// Description:

// Created:

// Author:

// Version:

// Vehicle Project:

LIN_description_file;
LIN_protocol_version = "2.1";
LIN_language_version = "2.1";
LIN_speed = 19.2 kbps;

Nodes {
  Master: VCU, 5 ms, 0.1 ms ;
  Slaves: ERV, EXV_1, EXV_2, PMP_1, PMP_2, SVA, HVCH ;
}

Signals {
  HVCH_IntelTemp: 8, 0, HVCH, VCU ;
  Calibration_sta: 2, 0, SVA, VCU ;
  Blockage_Fault_STA: 1, 0, SVA, VCU ;
  Breakage_Fault_STA: 1, 0, SVA, VCU ;
  Act_Pos_sta: 12, 0, SVA, VCU ;
  LIN_Resp_Error_sta: 1, 0, SVA, VCU ;
  EXV1_ResponseError: 1, 0, EXV_1, VCU ;
  EXV1_CurrentInitState: 2, 0, EXV_1, VCU ;
  EXV1_RunState: 1, 0, EXV_1, VCU ;
  EXV1_FaultState: 4, 0, EXV_1, VCU ;
  EXV1_VoltageState: 2, 0, EXV_1, VCU ;
  EXV1_TemperatureWarn: 2, 0, EXV_1, VCU ;
  EXV1_CurrentPosition: 16, 0, EXV_1, VCU ;
  HVCH_HV_DC_curr: 8, 0, HVCH, VCU ;
  HVCH_HV_voltage: 8, 0, HVCH, VCU ;
  HVCH_MediumTemp: 8, 0, HVCH, VCU ;
  HVCH_DutyCycle: 8, 50, HVCH, VCU ;
  HVCH_Status: 3, 0, HVCH, VCU ;
  HVCH_defectHeaterCircuits: 3, 0, HVCH, VCU ;
  HVCH_HV_Voltage_Valid: 2, 0, HVCH, VCU ;
  HVCH_TempSens_Flt: 1, 0, HVCH, VCU ;
  HVCH_TempLim: 1, 0, HVCH, VCU ;
  HVCH_LIN_Flt: 1, 0, HVCH, VCU ;
  HVCH_ExtPwrSup_Flt: 1, 0, HVCH, VCU ;
  HVCH_Off_ShrtCurr: 1, 0, HVCH, VCU ;
  HVCH_InternalPCBTemp: 8, 0, HVCH, VCU ;
  HVCH_CurrSens_Flt: 5, 0, HVCH, VCU ;
  HVCH_RsErr: 1, 0, HVCH, VCU ;
  RsErr_EXV2: 1, 0, ERV, VCU ;
  EXV2_curInit_Stat: 2, 0, ERV, VCU ;
  EXV2_Run_Stat: 1, 0, ERV, VCU ;
  EXV2_Fault_Stat: 4, 0, ERV, VCU ;
  EXV2_Volt_Stat: 2, 0, ERV, VCU ;
  EXV2_OvrTemp_Warn: 2, 0, ERV, VCU ;
  EXV2_Pos: 16, 0, ERV, VCU ;
  PMP3_RESP_ERROR: 1, 0, PMP_2, VCU ;
  PMP3_PumpMotorSta: 2, 0, PMP_2, VCU ;
  PMP3_PumpDryRunningSta: 1, 0, PMP_2, VCU ;
  PMP3_PumpPowerSta: 2, 0, PMP_2, VCU ;
  PMP3_PumpTempSta: 2, 0, PMP_2, VCU ;
  PMP3_PumpInputVolt: 8, 0, PMP_2, VCU ;
  PMP3_RealRPM: 8, 0, PMP_2, VCU ;
  Calibration_cmd: 1, 0, VCU, SVA ;
  Target_Pos_cmd: 12, 0, VCU, SVA ;
  EXV2_ResponseError: 1, 0, EXV_2, VCU ;
  EXV2_CurrentInitState: 2, 0, EXV_2, VCU ;
  EXV2_RunState: 1, 0, EXV_2, VCU ;
  EXV2_FaultState: 4, 0, EXV_2, VCU ;
  EXV2_VoltageState: 2, 0, EXV_2, VCU ;
  EXV2_TemperatureWarn: 2, 0, EXV_2, VCU ;
  EXV2_CurrentPosition: 16, 0, EXV_2, VCU ;
  ECC_PMP2_SpdSet: 8, 0, VCU, PMP_1 ;
  ECC_PMP3_SpdSet: 8, 0, VCU, PMP_2 ;
  EDCU_EXV2_Cmd_Set_Rq: 16, 0, VCU, ERV ;
  EDCU_EXV2_Cmd_Move_Enbl: 1, 0, VCU, ERV ;
  EDCU_EXV2_Cmd_Init_Rq: 3, 0, VCU, ERV ;
  TMM_EXV2_PositionRequest: 16, 0, VCU, EXV_2 ;
  TMM_EXV2_EnableRequest: 1, 0, VCU, EXV_2 ;
  TMM_EXV2_initRequest: 3, 0, VCU, EXV_2 ;
  TMM_EXV1_PositionRequest: 16, 0, VCU, EXV_1 ;
  TMM_EXV1_EnableRequest: 1, 0, VCU, EXV_1 ;
  TMM_EXV1_initRequest: 3, 0, VCU, EXV_1 ;
  PMP2_RESP_ERROR: 1, 0, PMP_1, VCU ;
  PMP2_PumpMotorSta: 2, 0, PMP_1, VCU ;
  PMP2_PumpDryRunningSta: 1, 0, PMP_1, VCU ;
  PMP2_PumpPowerSta: 2, 0, PMP_1, VCU ;
  PMP2_PumpTempSta: 2, 0, PMP_1, VCU ;
  PMP2_PumpInputVolt: 8, 0, PMP_1, VCU ;
  PMP2_RealRPM: 8, 0, PMP_1, VCU ;
  TCU_HVCH_heating_rq: 7, 0, VCU, HVCH ;
  TCU_HVCH_On_Rq: 2, 0, VCU, HVCH ;
  TCU_HVCHMaxPowerLimit: 8, 0, VCU, HVCH ;
  TCU_HVCH_TmaxLim_output: 8, 0, VCU, HVCH ;
}

Frames {
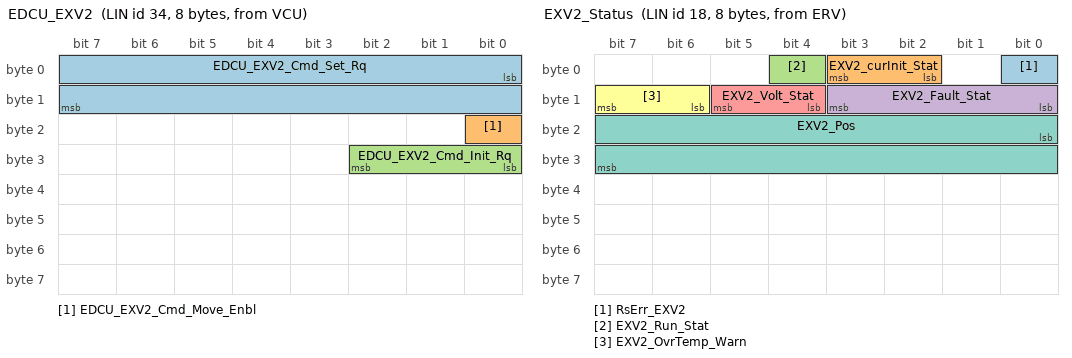
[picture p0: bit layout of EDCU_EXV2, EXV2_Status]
  EDCU_EXV2: 34, VCU, 8 {
    EDCU_EXV2_Cmd_Set_Rq, 0 ;
    EDCU_EXV2_Cmd_Move_Enbl, 16 ;
    EDCU_EXV2_Cmd_Init_Rq, 24 ;
  }
  EXV2_Status: 18, ERV, 8 {
    RsErr_EXV2, 0 ;
    EXV2_curInit_Stat, 2 ;
    EXV2_Run_Stat, 4 ;
    EXV2_Fault_Stat, 8 ;
    EXV2_Volt_Stat, 12 ;
    EXV2_OvrTemp_Warn, 14 ;
    EXV2_Pos, 16 ;
  }
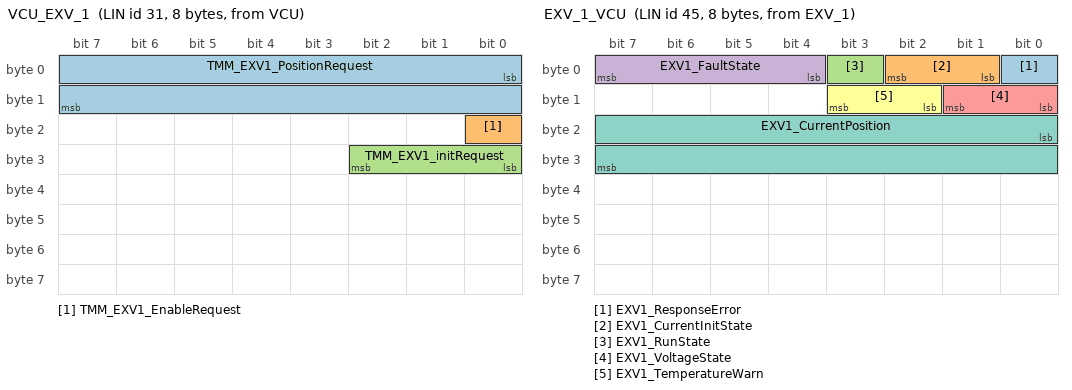
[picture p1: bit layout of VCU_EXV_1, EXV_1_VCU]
  VCU_EXV_1: 31, VCU, 8 {
    TMM_EXV1_PositionRequest, 0 ;
    TMM_EXV1_EnableRequest, 16 ;
    TMM_EXV1_initRequest, 24 ;
  }
  EXV_1_VCU: 45, EXV_1, 8 {
    EXV1_ResponseError, 0 ;
    EXV1_CurrentInitState, 1 ;
    EXV1_RunState, 3 ;
    EXV1_FaultState, 4 ;
    EXV1_VoltageState, 8 ;
    EXV1_TemperatureWarn, 10 ;
    EXV1_CurrentPosition, 16 ;
  }
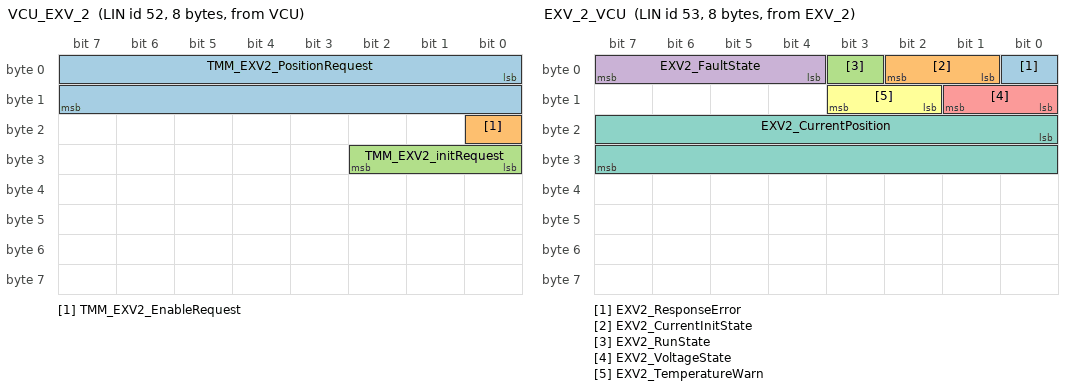
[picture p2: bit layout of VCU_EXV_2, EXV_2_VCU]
  VCU_EXV_2: 52, VCU, 8 {
    TMM_EXV2_PositionRequest, 0 ;
    TMM_EXV2_EnableRequest, 16 ;
    TMM_EXV2_initRequest, 24 ;
  }
  EXV_2_VCU: 53, EXV_2, 8 {
    EXV2_ResponseError, 0 ;
    EXV2_CurrentInitState, 1 ;
    EXV2_RunState, 3 ;
    EXV2_FaultState, 4 ;
    EXV2_VoltageState, 8 ;
    EXV2_TemperatureWarn, 10 ;
    EXV2_CurrentPosition, 16 ;
  }
  PMP_Cmd: 36, VCU, 8 {
    ECC_PMP2_SpdSet, 8 ;
    ECC_PMP3_SpdSet, 16 ;
  }
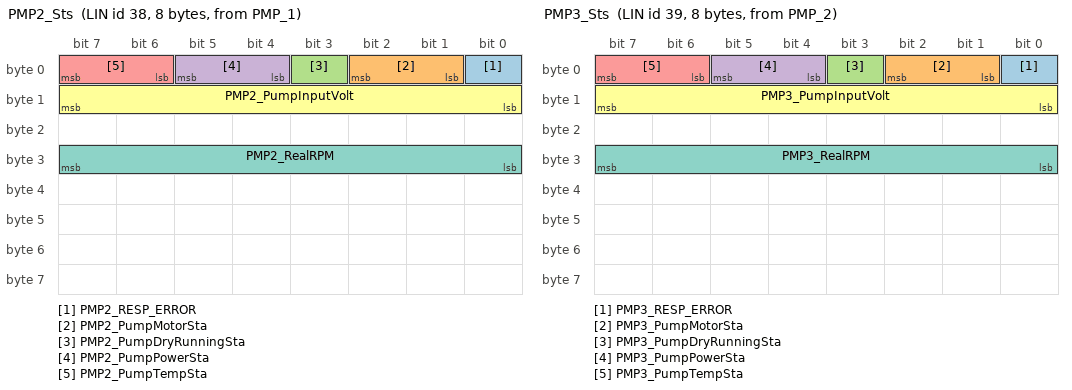
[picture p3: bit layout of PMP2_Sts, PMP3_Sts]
  PMP2_Sts: 38, PMP_1, 8 {
    PMP2_RESP_ERROR, 0 ;
    PMP2_PumpMotorSta, 1 ;
    PMP2_PumpDryRunningSta, 3 ;
    PMP2_PumpPowerSta, 4 ;
    PMP2_PumpTempSta, 6 ;
    PMP2_PumpInputVolt, 8 ;
    PMP2_RealRPM, 24 ;
  }
  PMP3_Sts: 39, PMP_2, 8 {
    PMP3_RESP_ERROR, 0 ;
    PMP3_PumpMotorSta, 1 ;
    PMP3_PumpDryRunningSta, 3 ;
    PMP3_PumpPowerSta, 4 ;
    PMP3_PumpTempSta, 6 ;
    PMP3_PumpInputVolt, 8 ;
    PMP3_RealRPM, 24 ;
  }
  VCU_SVA_CMD: 16, VCU, 8 {
    Calibration_cmd, 8 ;
    Target_Pos_cmd, 16 ;
  }
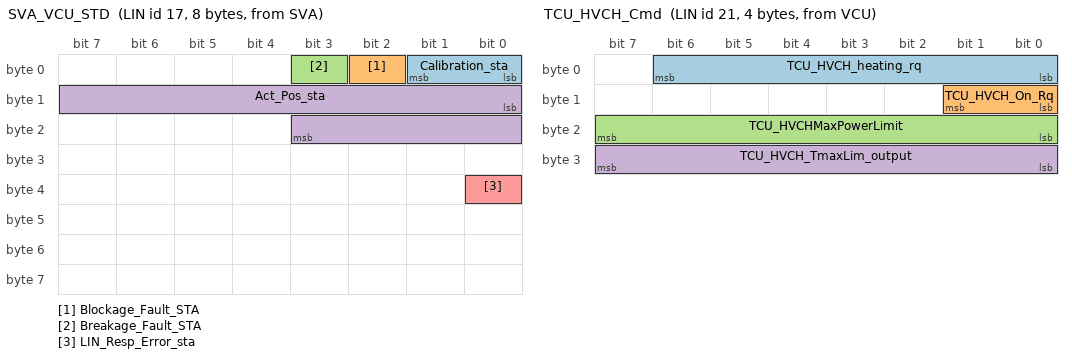
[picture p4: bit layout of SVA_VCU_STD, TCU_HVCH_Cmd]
  SVA_VCU_STD: 17, SVA, 8 {
    Calibration_sta, 0 ;
    Blockage_Fault_STA, 2 ;
    Breakage_Fault_STA, 3 ;
    Act_Pos_sta, 8 ;
    LIN_Resp_Error_sta, 32 ;
  }
  TCU_HVCH_Cmd: 21, VCU, 4 {
    TCU_HVCH_heating_rq, 0 ;
    TCU_HVCH_On_Rq, 8 ;
    TCU_HVCHMaxPowerLimit, 16 ;
    TCU_HVCH_TmaxLim_output, 24 ;
  }
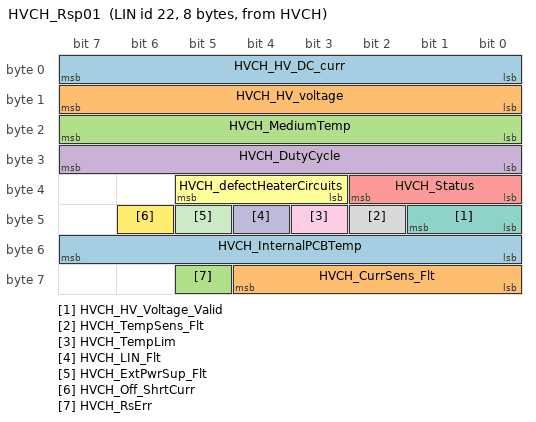
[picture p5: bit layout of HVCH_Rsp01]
  HVCH_Rsp01: 22, HVCH, 8 {
    HVCH_HV_DC_curr, 0 ;
    HVCH_HV_voltage, 8 ;
    HVCH_MediumTemp, 16 ;
    HVCH_DutyCycle, 24 ;
    HVCH_Status, 32 ;
    HVCH_defectHeaterCircuits, 35 ;
    HVCH_HV_Voltage_Valid, 40 ;
    HVCH_TempSens_Flt, 42 ;
    HVCH_TempLim, 43 ;
    HVCH_LIN_Flt, 44 ;
    HVCH_ExtPwrSup_Flt, 45 ;
    HVCH_Off_ShrtCurr, 46 ;
    HVCH_InternalPCBTemp, 48 ;
    HVCH_CurrSens_Flt, 56 ;
    HVCH_RsErr, 61 ;
  }
  HVCH_Rsp02: 23, HVCH, 8 {
    HVCH_IntelTemp, 0 ;
  }
}

Node_attributes {
  ERV{
    LIN_protocol = "2.1" ;
    configured_NAD = 0x62 ;
    initial_NAD = 0x62 ;
    product_id = 0x0, 0x0, 0 ;
    P2_min = 50 ms ;
    ST_min = 0 ms ;
    N_As_timeout = 1000 ms ;
    N_Cr_timeout = 1000 ms ;
    configurable_frames {
      EDCU_EXV2 ;
      EXV2_Status ;
    }
  }
  EXV_1{
    LIN_protocol = "2.1" ;
    configured_NAD = 0x63 ;
    initial_NAD = 0x63 ;
    product_id = 0x0, 0x0, 0 ;
    P2_min = 50 ms ;
    ST_min = 0 ms ;
    N_As_timeout = 1000 ms ;
    N_Cr_timeout = 1000 ms ;
    configurable_frames {
      VCU_EXV_1 ;
      EXV_1_VCU ;
    }
  }
  EXV_2{
    LIN_protocol = "2.1" ;
    configured_NAD = 0x64 ;
    initial_NAD = 0x64 ;
    product_id = 0x0, 0x0, 0 ;
    P2_min = 50 ms ;
    ST_min = 0 ms ;
    N_As_timeout = 1000 ms ;
    N_Cr_timeout = 1000 ms ;
    configurable_frames {
      VCU_EXV_2 ;
      EXV_2_VCU ;
    }
  }
  PMP_1{
    LIN_protocol = "2.1" ;
    configured_NAD = 0x74 ;
    initial_NAD = 0x74 ;
    product_id = 0x0, 0x0, 0 ;
    P2_min = 50 ms ;
    ST_min = 0 ms ;
    N_As_timeout = 1000 ms ;
    N_Cr_timeout = 1000 ms ;
    configurable_frames {
      PMP_Cmd ;
      PMP2_Sts ;
    }
  }
  PMP_2{
    LIN_protocol = "2.1" ;
    configured_NAD = 0x75 ;
    initial_NAD = 0x75 ;
    product_id = 0x0, 0x0, 0 ;
    P2_min = 50 ms ;
    ST_min = 0 ms ;
    N_As_timeout = 1000 ms ;
    N_Cr_timeout = 1000 ms ;
    configurable_frames {
      PMP_Cmd ;
      PMP3_Sts ;
    }
  }
  SVA{
    LIN_protocol = "2.1" ;
    configured_NAD = 0x65 ;
    initial_NAD = 0x65 ;
    product_id = 0x0, 0x0, 0 ;
    P2_min = 50 ms ;
    ST_min = 0 ms ;
    N_As_timeout = 1000 ms ;
    N_Cr_timeout = 1000 ms ;
    configurable_frames {
      VCU_SVA_CMD ;
      SVA_VCU_STD ;
    }
  }
  HVCH{
    LIN_protocol = "2.1" ;
    configured_NAD = 0x5B ;
    initial_NAD = 0x5B ;
    product_id = 0x0, 0x0, 0 ;
    P2_min = 50 ms ;
    ST_min = 0 ms ;
    N_As_timeout = 1000 ms ;
    N_Cr_timeout = 1000 ms ;
    configurable_frames {
      TCU_HVCH_Cmd ;
      HVCH_Rsp01 ;
      HVCH_Rsp02 ;
    }
  }
}

Schedule_tables {
 TCU_LIN_Schedule {
    EDCU_EXV2 delay 10 ms ;
    EXV2_Status delay 10 ms ;
    VCU_EXV_1 delay 100 ms ;
    EXV_1_VCU delay 100 ms ;
    VCU_EXV_2 delay 100 ms ;
    EXV_2_VCU delay 100 ms ;
    PMP_Cmd delay 10 ms ;
    PMP2_Sts delay 10 ms ;
    PMP3_Sts delay 10 ms ;
    VCU_SVA_CMD delay 15 ms ;
    SVA_VCU_STD delay 15 ms ;
    TCU_HVCH_Cmd delay 20 ms ;
    HVCH_Rsp01 delay 20 ms ;
    HVCH_Rsp02 delay 20 ms ;
  }
}

Signal_encoding_types {
  Act_Pos_sta {
    physical_value, 0, 3600, 0.1, -5, "Degree" ;
  }
  Blockage_Fault_STA {
    physical_value, 0, 2, 1, 0 ;
    logical_value, 0, " False" ;
    logical_value, 1, " True" ;
  }
  Breakage_Fault_STA {
    physical_value, 0, 2, 1, 0 ;
    logical_value, 0, " False" ;
    logical_value, 1, " True" ;
  }
  Calibration_cmd {
    physical_value, 0, 1, 1, 0 ;
    logical_value, 0, "Normal" ;
    logical_value, 1, "SVA performs calibration" ;
  }
  Calibration_sta {
    physical_value, 0, 3, 1, 0 ;
    logical_value, 0, "not calibration" ;
    logical_value, 1, "calibration ongoing" ;
    logical_value, 2, "calibration finished" ;
    logical_value, 3, " calibration failed" ;
  }
  ECC_PMP2_SpdSet {
    physical_value, 0, 100, 0.4, 0, "%" ;
  }
  ECC_PMP3_SpdSet {
    physical_value, 0, 100, 0.4, 0, "%" ;
  }
  EDCU_EXV2_Cmd_Init_Rq {
    physical_value, 0, 7, 1, 0 ;
    logical_value, 0, "NO_RQ" ;
    logical_value, 1, "START_INIT_SQC" ;
    logical_value, 2, "WAIT_SQC_FINISH" ;
  }
  EDCU_EXV2_Cmd_Move_Enbl {
    physical_value, 0, 1, 1, 0 ;
    logical_value, 0, "DSABL" ;
    logical_value, 1, "ENBL" ;
  }
  EDCU_EXV2_Cmd_Set_Rq {
    physical_value, 0, 576, 1, 0 ;
  }
  EXV1_CurrentInitState {
    physical_value, 0, 3, 1, 0 ;
    logical_value, 0, "  NO_INIT" ;
    logical_value, 1, "  INIT_IN_PROCESS" ;
    logical_value, 2, "  Initialized" ;
  }
  EXV1_CurrentPosition {
    physical_value, 0, 500, 1, 0 ;
  }
  EXV1_FaultState {
    physical_value, 0, 4, 1, 0 ;
    logical_value, 0, " No Fault" ;
    logical_value, 1, " COIL_SHRT" ;
    logical_value, 2, " COIL_OPN" ;
    logical_value, 3, "  Over temp shut down" ;
    logical_value, 4, "  Reserved" ;
  }
  EXV1_ResponseError {
    physical_value, 0, 1, 1, 0 ;
    logical_value, 0, "No Comm Error" ;
    logical_value, 1, " Comm Error Active" ;
  }
  EXV1_RunState {
    physical_value, 0, 1, 1, 0 ;
    logical_value, 0, "NO_MOVEMENT" ;
    logical_value, 1, "ACT_MOVING" ;
  }
  EXV1_TemperatureWarn {
    physical_value, 0, 1, 1, 0 ;
    logical_value, 0, " OK " ;
    logical_value, 1, " WARNING" ;
  }
  EXV1_VoltageState {
    physical_value, 0, 2, 1, 0 ;
    logical_value, 0, " Voltage Range OK " ;
    logical_value, 1, " Over Voltage " ;
    logical_value, 2, " Under Voltage" ;
  }
  EXV2_CurrentInitState {
    physical_value, 0, 3, 1, 0 ;
    logical_value, 0, "  NO_INIT" ;
    logical_value, 1, "  INIT_IN_PROCESS" ;
    logical_value, 2, "  Initialized" ;
  }
  EXV2_CurrentPosition {
    physical_value, 0, 500, 1, 0 ;
  }
  EXV2_FaultState {
    physical_value, 0, 4, 1, 0 ;
    logical_value, 0, " No Fault" ;
    logical_value, 1, " COIL_SHRT" ;
    logical_value, 2, " COIL_OPN" ;
    logical_value, 3, "  Over temp shut down" ;
    logical_value, 4, "  Reserved" ;
  }
  EXV2_Fault_Stat {
    physical_value, 0, 4, 1, 0 ;
    logical_value, 0, "Actuator Not Faulted" ;
    logical_value, 1, "Motor-Coil shorted" ;
    logical_value, 2, "Motor-Coil open load" ;
    logical_value, 3, "Over temperature shutdown" ;
    logical_value, 4, "not defined" ;
    logical_value, 5, "Motor_Stall?????????" ;
  }
  EXV2_OvrTemp_Warn {
    physical_value, 0, 1, 1, 0 ;
    logical_value, 0, "Ok" ;
    logical_value, 1, "High Temperature Warning" ;
    logical_value, 2, "not defined" ;
    logical_value, 3, "not defined" ;
  }
  EXV2_Pos {
    physical_value, 0, 576, 1, 0 ;
  }
  EXV2_ResponseError {
    physical_value, 0, 1, 1, 0 ;
    logical_value, 0, "No Comm Error" ;
    logical_value, 1, " Comm Error Active" ;
  }
  EXV2_RunState {
    physical_value, 0, 1, 1, 0 ;
    logical_value, 0, "NO_MOVEMENT" ;
    logical_value, 1, "ACT_MOVING" ;
  }
  EXV2_Run_Stat {
    physical_value, 0, 1, 1, 0 ;
    logical_value, 0, "NO_MOVEMENT" ;
    logical_value, 1, "ACT_MOVING" ;
  }
  EXV2_TemperatureWarn {
    physical_value, 0, 1, 1, 0 ;
    logical_value, 0, " OK " ;
    logical_value, 1, " WARNING" ;
  }
  EXV2_Volt_Stat {
    physical_value, 0, 2, 1, 0 ;
    logical_value, 0, "VOLT_RANGE_OK" ;
    logical_value, 1, "OVERVOLTAGE" ;
    logical_value, 2, "UNDERVOLTAGE" ;
    logical_value, 3, "not defined" ;
  }
  EXV2_VoltageState {
    physical_value, 0, 2, 1, 0 ;
    logical_value, 0, " Voltage Range OK " ;
    logical_value, 1, " Over Voltage " ;
    logical_value, 2, " Under Voltage" ;
  }
  EXV2_curInit_Stat {
    physical_value, 0, 3, 1, 0 ;
    logical_value, 0, "NO_INIT" ;
    logical_value, 1, "INIT_IN_PROCESS" ;
    logical_value, 2, "INIT_READY" ;
    logical_value, 3, "Invalid" ;
  }
  HVCH_CurrSens_Flt {
    physical_value, 0, 31, 1, 0 ;
    logical_value, 0, "Diagnostic pending" ;
    logical_value, 1, "Diagnostic passed" ;
    logical_value, 2, "0x2~0x1F, Reserve" ;
  }
  HVCH_DutyCycle {
    physical_value, 0, 150, 1, -50, "percent" ;
    logical_value, 0, "0x00~0x96, Valid value" ;
    logical_value, 255, "invalid" ;
  }
  HVCH_ExtPwrSup_Flt {
    physical_value, 0, 1, 1, 0 ;
    logical_value, 0, "Battery voltage okay" ;
    logical_value, 1, "Battery voltage off" ;
  }
  HVCH_HV_DC_curr {
    physical_value, 0, 254, 0.25, 0, "A" ;
    logical_value, 0, "0x00~0xFE, Valid value" ;
    logical_value, 255, "invalid" ;
  }
  HVCH_HV_Voltage_Valid {
    physical_value, 0, 3, 1, 0 ;
    logical_value, 0, "NO HV detected" ;
    logical_value, 1, "HV valid" ;
    logical_value, 2, "Under Voltage" ;
    logical_value, 3, "Over Voltage" ;
  }
  HVCH_HV_voltage {
    physical_value, 0, 254, 2, 0, "V" ;
    logical_value, 0, "0x00~0xFE, Valid value" ;
    logical_value, 255, "invalid" ;
  }
  HVCH_IntelTemp {
    physical_value, 0, 254, 1, -50, "celsius" ;
    logical_value, 0, "0x00~0xFE, Valid value" ;
    logical_value, 255, "invalid" ;
  }
  HVCH_InternalPCBTemp {
    physical_value, 0, 254, 1, -50 ;
    logical_value, 0, "0x00~0xFE, Valid value" ;
    logical_value, 255, "invalid" ;
  }
  HVCH_LIN_Flt {
    physical_value, 0, 1, 1, 0 ;
    logical_value, 0, "No LIN timeout detected" ;
    logical_value, 1, "LIN timeout active" ;
  }
  HVCH_MediumTemp {
    physical_value, 0, 254, 1, -50, "celsius" ;
    logical_value, 0, "0x00~0xFE, Valid value" ;
    logical_value, 255, "invalid" ;
  }
  HVCH_Off_ShrtCurr {
    physical_value, 0, 1, 1, 0 ;
    logical_value, 0, "No short detected" ;
    logical_value, 1, "Short detected" ;
  }
  HVCH_RsErr {
    physical_value, 0, 1, 1, 0 ;
    logical_value, 0, "No LIN response error detected" ;
    logical_value, 1, "LIN response error active" ;
  }
  HVCH_Status {
    physical_value, 0, 7, 1, 0 ;
    logical_value, 0, "HV PTC off / HVCH_OFF" ;
    logical_value, 1, "HV PTC on / HVCH_ON" ;
    logical_value, 2, "0x2~0x7, SNA" ;
  }
  HVCH_TempLim {
    physical_value, 0, 1, 1, 0 ;
    logical_value, 0, "No over temperature detected" ;
    logical_value, 1, "Over temp. situation active" ;
  }
  HVCH_TempSens_Flt {
    physical_value, 0, 1, 1, 0 ;
    logical_value, 0, "No fault" ;
    logical_value, 1, "fault" ;
  }
  HVCH_defectHeaterCircuits {
    physical_value, 0, 7, 1, 0 ;
    logical_value, 0, "No defect" ;
    logical_value, 1, "Leg 1 defect" ;
    logical_value, 2, "Leg 2 defect" ;
    logical_value, 3, "Leg 1 + 2 defect" ;
    logical_value, 4, "Leg 3 defect" ;
    logical_value, 5, "Leg 1 + 3 defect" ;
    logical_value, 6, "Leg 2 + 3 defect" ;
    logical_value, 7, "Leg 1 + 2 + 3 defect" ;
  }
  LIN_Resp_Error_sta {
    physical_value, 0, 2, 1, 0 ;
    logical_value, 0, " False" ;
    logical_value, 1, " True" ;
  }
  PMP2_PumpDryRunningSta {
    physical_value, 0, 1, 1, 0 ;
    logical_value, 0, "Normal" ;
    logical_value, 1, "DryRun" ;
  }
  PMP2_PumpInputVolt {
    physical_value, 0, 30, 0.1, 0, "V" ;
  }
  PMP2_PumpMotorSta {
    physical_value, 0, 3, 1, 0 ;
    logical_value, 0, "Normal" ;
    logical_value, 1, "ShortCircuit" ;
    logical_value, 2, "OpenCircuit" ;
    logical_value, 3, "Stall" ;
  }
  PMP2_PumpPowerSta {
    physical_value, 0, 3, 1, 0 ;
    logical_value, 0, "Normal" ;
    logical_value, 1, "OverVol" ;
    logical_value, 2, "BelowVol" ;
    logical_value, 3, "Reserved" ;
  }
  PMP2_PumpTempSta {
    physical_value, 0, 3, 1, 0 ;
    logical_value, 0, "Normal" ;
    logical_value, 1, "OverTempReduction" ;
    logical_value, 2, "OverTempShutDown" ;
    logical_value, 3, "Reserved" ;
  }
  PMP2_RESP_ERROR {
    physical_value, 0, 1, 1, 0 ;
    logical_value, 0, "Normal" ;
    logical_value, 1, "Error" ;
  }
  PMP2_RealRPM {
    physical_value, 0, 100, 0.4, 0, "%" ;
  }
  PMP3_PumpDryRunningSta {
    physical_value, 0, 1, 1, 0 ;
    logical_value, 0, "Normal" ;
    logical_value, 1, "DryRun" ;
  }
  PMP3_PumpInputVolt {
    physical_value, 0, 30, 0.1, 0, "V" ;
  }
  PMP3_PumpMotorSta {
    physical_value, 0, 3, 1, 0 ;
    logical_value, 0, "Normal" ;
    logical_value, 1, "ShortCircuit" ;
    logical_value, 2, "OpenCircuit" ;
    logical_value, 3, "Stall" ;
  }
  PMP3_PumpPowerSta {
    physical_value, 0, 3, 1, 0 ;
    logical_value, 0, "Normal" ;
    logical_value, 1, "OverVol" ;
    logical_value, 2, "BelowVol" ;
    logical_value, 3, "Reserved" ;
  }
  PMP3_PumpTempSta {
    physical_value, 0, 3, 1, 0 ;
    logical_value, 0, "Normal" ;
    logical_value, 1, "OverTempReduction" ;
    logical_value, 2, "OverTempShutDown" ;
    logical_value, 3, "Reserved" ;
  }
  PMP3_RESP_ERROR {
    physical_value, 0, 1, 1, 0 ;
    logical_value, 0, "Normal" ;
    logical_value, 1, "Error" ;
  }
  PMP3_RealRPM {
    physical_value, 0, 100, 0.4, 0, "%" ;
  }
  RsErr_EXV2 {
    physical_value, 0, 0, 1, 0 ;
    logical_value, 0, "NO COMM ERROR" ;
    logical_value, 1, "COMM ERROR DETECTED" ;
  }
  TCU_HVCHMaxPowerLimit {
    physical_value, 0, 254, 0.04, 0, "KW" ;
    logical_value, 0, "0x00~0xFE, Valid value" ;
    logical_value, 255, "invalid" ;
  }
  TCU_HVCH_On_Rq {
    physical_value, 0, 3, 1, 0 ;
    logical_value, 0, "PTC_OFF" ;
    logical_value, 1, "PTC_ON" ;
    logical_value, 2, "reserved / RES" ;
    logical_value, 3, "SNA" ;
  }
  TCU_HVCH_TmaxLim_output {
    physical_value, 0, 254, 1, -50, "celsius" ;
    logical_value, 0, "0x00~0xFE, Valid value" ;
    logical_value, 255, "invalid" ;
  }
  TCU_HVCH_heating_rq {
    physical_value, 0, 100, 1, 0, "percent" ;
    logical_value, 0, "Level0" ;
    logical_value, 1, "Level1" ;
    logical_value, 2, "Level2" ;
    logical_value, 3, "Level3" ;
    logical_value, 4, "Level4" ;
    logical_value, 5, "Level5" ;
    logical_value, 6, "Level6" ;
    logical_value, 7, "Reserve" ;
  }
  TMM_EXV1_EnableRequest {
    physical_value, 0, 1, 1, 0 ;
    logical_value, 0, " EXVNotEnable" ;
    logical_value, 1, " EXVEnable" ;
  }
  TMM_EXV1_PositionRequest {
    physical_value, 0, 500, 1, 0 ;
  }
  TMM_EXV1_initRequest {
    physical_value, 0, 7, 1, 0 ;
    logical_value, 0, "NO_RQ" ;
    logical_value, 1, " InitializationReq  " ;
    logical_value, 2, " waiting for Sequence to finish" ;
  }
  TMM_EXV2_EnableRequest {
    physical_value, 0, 1, 1, 0 ;
    logical_value, 0, " EXVNotEnable" ;
    logical_value, 1, " EXVEnable" ;
  }
  TMM_EXV2_PositionRequest {
    physical_value, 0, 500, 1, 0 ;
  }
  TMM_EXV2_initRequest {
    physical_value, 0, 7, 1, 0 ;
    logical_value, 0, "NO_RQ" ;
    logical_value, 1, " InitializationReq  " ;
    logical_value, 2, " waiting for Sequence to finish" ;
  }
  Target_Pos_cmd {
    physical_value, 0, 3600, 0.1, -5, "Degree" ;
  }
}

Signal_representation {
  Act_Pos_sta: Act_Pos_sta ;
  Blockage_Fault_STA: Blockage_Fault_STA ;
  Breakage_Fault_STA: Breakage_Fault_STA ;
  Calibration_cmd: Calibration_cmd ;
  Calibration_sta: Calibration_sta ;
  ECC_PMP2_SpdSet: ECC_PMP2_SpdSet ;
  ECC_PMP3_SpdSet: ECC_PMP3_SpdSet ;
  EDCU_EXV2_Cmd_Init_Rq: EDCU_EXV2_Cmd_Init_Rq ;
  EDCU_EXV2_Cmd_Move_Enbl: EDCU_EXV2_Cmd_Move_Enbl ;
  EDCU_EXV2_Cmd_Set_Rq: EDCU_EXV2_Cmd_Set_Rq ;
  EXV1_CurrentInitState: EXV1_CurrentInitState ;
  EXV1_CurrentPosition: EXV1_CurrentPosition ;
  EXV1_FaultState: EXV1_FaultState ;
  EXV1_ResponseError: EXV1_ResponseError ;
  EXV1_RunState: EXV1_RunState ;
  EXV1_TemperatureWarn: EXV1_TemperatureWarn ;
  EXV1_VoltageState: EXV1_VoltageState ;
  EXV2_CurrentInitState: EXV2_CurrentInitState ;
  EXV2_CurrentPosition: EXV2_CurrentPosition ;
  EXV2_FaultState: EXV2_FaultState ;
  EXV2_Fault_Stat: EXV2_Fault_Stat ;
  EXV2_OvrTemp_Warn: EXV2_OvrTemp_Warn ;
  EXV2_Pos: EXV2_Pos ;
  EXV2_ResponseError: EXV2_ResponseError ;
  EXV2_RunState: EXV2_RunState ;
  EXV2_Run_Stat: EXV2_Run_Stat ;
  EXV2_TemperatureWarn: EXV2_TemperatureWarn ;
  EXV2_Volt_Stat: EXV2_Volt_Stat ;
  EXV2_VoltageState: EXV2_VoltageState ;
  EXV2_curInit_Stat: EXV2_curInit_Stat ;
  HVCH_CurrSens_Flt: HVCH_CurrSens_Flt ;
  HVCH_DutyCycle: HVCH_DutyCycle ;
  HVCH_ExtPwrSup_Flt: HVCH_ExtPwrSup_Flt ;
  HVCH_HV_DC_curr: HVCH_HV_DC_curr ;
  HVCH_HV_Voltage_Valid: HVCH_HV_Voltage_Valid ;
  HVCH_HV_voltage: HVCH_HV_voltage ;
  HVCH_IntelTemp: HVCH_IntelTemp ;
  HVCH_InternalPCBTemp: HVCH_InternalPCBTemp ;
  HVCH_LIN_Flt: HVCH_LIN_Flt ;
  HVCH_MediumTemp: HVCH_MediumTemp ;
  HVCH_Off_ShrtCurr: HVCH_Off_ShrtCurr ;
  HVCH_RsErr: HVCH_RsErr ;
  HVCH_Status: HVCH_Status ;
  HVCH_TempLim: HVCH_TempLim ;
  HVCH_TempSens_Flt: HVCH_TempSens_Flt ;
  HVCH_defectHeaterCircuits: HVCH_defectHeaterCircuits ;
  LIN_Resp_Error_sta: LIN_Resp_Error_sta ;
  PMP2_PumpDryRunningSta: PMP2_PumpDryRunningSta ;
  PMP2_PumpInputVolt: PMP2_PumpInputVolt ;
  PMP2_PumpMotorSta: PMP2_PumpMotorSta ;
  PMP2_PumpPowerSta: PMP2_PumpPowerSta ;
  PMP2_PumpTempSta: PMP2_PumpTempSta ;
  PMP2_RESP_ERROR: PMP2_RESP_ERROR ;
  PMP2_RealRPM: PMP2_RealRPM ;
  PMP3_PumpDryRunningSta: PMP3_PumpDryRunningSta ;
  PMP3_PumpInputVolt: PMP3_PumpInputVolt ;
  PMP3_PumpMotorSta: PMP3_PumpMotorSta ;
  PMP3_PumpPowerSta: PMP3_PumpPowerSta ;
  PMP3_PumpTempSta: PMP3_PumpTempSta ;
  PMP3_RESP_ERROR: PMP3_RESP_ERROR ;
  PMP3_RealRPM: PMP3_RealRPM ;
  RsErr_EXV2: RsErr_EXV2 ;
  TCU_HVCHMaxPowerLimit: TCU_HVCHMaxPowerLimit ;
  TCU_HVCH_On_Rq: TCU_HVCH_On_Rq ;
  TCU_HVCH_TmaxLim_output: TCU_HVCH_TmaxLim_output ;
  TCU_HVCH_heating_rq: TCU_HVCH_heating_rq ;
  TMM_EXV1_EnableRequest: TMM_EXV1_EnableRequest ;
  TMM_EXV1_PositionRequest: TMM_EXV1_PositionRequest ;
  TMM_EXV1_initRequest: TMM_EXV1_initRequest ;
  TMM_EXV2_EnableRequest: TMM_EXV2_EnableRequest ;
  TMM_EXV2_PositionRequest: TMM_EXV2_PositionRequest ;
  TMM_EXV2_initRequest: TMM_EXV2_initRequest ;
  Target_Pos_cmd: Target_Pos_cmd ;
}
